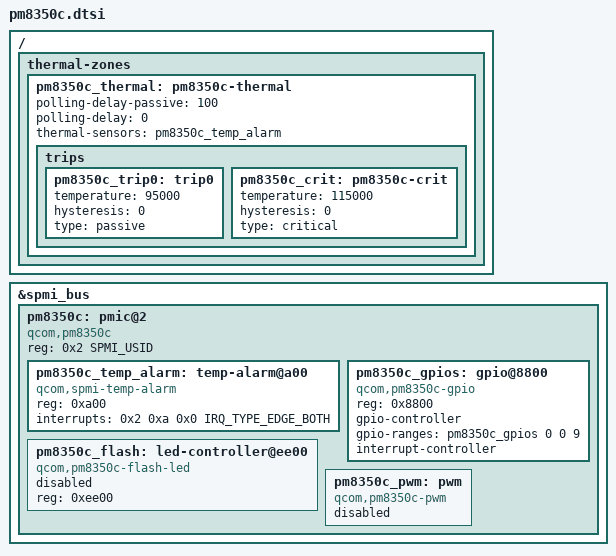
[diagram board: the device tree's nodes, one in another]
// SPDX-License-Identifier: BSD-3-Clause
/*
 * Copyright (c) 2021, Linaro Limited
 */

#include <dt-bindings/interrupt-controller/irq.h>
#include <dt-bindings/spmi/spmi.h>

&spmi_bus {
	pm8350c: pmic@2 {
		compatible = "qcom,pm8350c", "qcom,spmi-pmic";
		reg = <0x2 SPMI_USID>;
		#address-cells = <1>;
		#size-cells = <0>;

		pm8350c_temp_alarm: temp-alarm@a00 {
			compatible = "qcom,spmi-temp-alarm";
			reg = <0xa00>;
			interrupts = <0x2 0xa 0x0 IRQ_TYPE_EDGE_BOTH>;
			#thermal-sensor-cells = <0>;
		};

		pm8350c_gpios: gpio@8800 {
			compatible = "qcom,pm8350c-gpio", "qcom,spmi-gpio";
			reg = <0x8800>;
			gpio-controller;
			gpio-ranges = <&pm8350c_gpios 0 0 9>;
			#gpio-cells = <2>;
			interrupt-controller;
			#interrupt-cells = <2>;
		};

		pm8350c_flash: led-controller@ee00 {
			compatible = "qcom,pm8350c-flash-led", "qcom,spmi-flash-led";
			reg = <0xee00>;
			status = "disabled";
		};

		pm8350c_pwm: pwm {
			compatible = "qcom,pm8350c-pwm";
			#pwm-cells = <2>;
			status = "disabled";
		};
	};
};

/ {
	thermal-zones {
		pm8350c_thermal: pm8350c-thermal {
			polling-delay-passive = <100>;
			polling-delay = <0>;
			thermal-sensors = <&pm8350c_temp_alarm>;

			trips {
				pm8350c_trip0: trip0 {
					temperature = <95000>;
					hysteresis = <0>;
					type = "passive";
				};

				pm8350c_crit: pm8350c-crit {
					temperature = <115000>;
					hysteresis = <0>;
					type = "critical";
				};
			};
		};
	};
};
